# MIMXRT1015 register map
Vendor: nxp.com; File version: 1.0
CPU: CM7 r0p1, little endian, MPU, FPU, VTOR, 4 interrupt priority bits
Registers are 32-bit, read-write, reset 0x0 unless marked. A register's access mark holds for its fields unless they carry their own. Offsets are from the block's base; [hi:lo] are bit positions; {n}, {i} and the like mark numbered series; 'fields as' and 'values as' point back to an identical list.

## IOMUXC (part 2 of 2)
Base 0x401F8000; register names take the prefix IOMUXC_
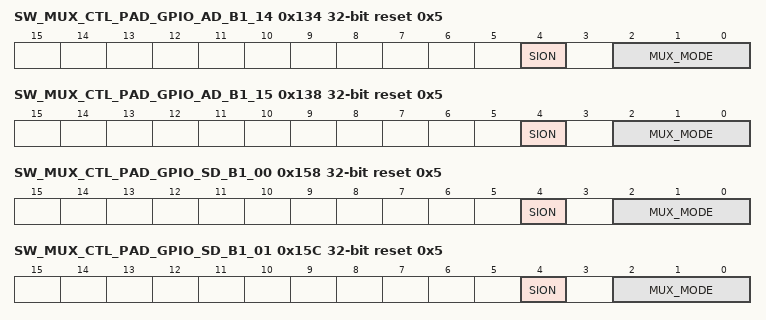
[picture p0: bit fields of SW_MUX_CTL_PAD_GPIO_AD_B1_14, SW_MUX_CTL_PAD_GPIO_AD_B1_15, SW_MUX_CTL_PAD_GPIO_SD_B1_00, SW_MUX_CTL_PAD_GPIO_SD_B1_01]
0x134 SW_MUX_CTL_PAD_GPIO_AD_B1_14 reset 0x5 — SW_MUX_CTL_PAD_GPIO_AD_B1_14 SW MUX Control Register
  [4] SION — Software Input On Field.
    0=DISABLED (Input Path is determined by functionality); 1=ENABLED (Force input path of pad GPIO_AD_B1_14)
  [2:0] MUX_MODE — MUX Mode Select Field.
    0=ALT0 (Select mux mode: ALT0 mux port: LPI2C1_SCL of instance: lpi2c1); 1=ALT1 (Select mux mode: ALT1 mux port: ACMP_OUT02 of instance: acmp); 4=ALT4 (Select mux mode: ALT4 mux port: FLEXIO1_FLEXIO01 of instance: flexio1); 5=ALT5 (Select mux mode: ALT5 mux port: GPIO1_IO30 of instance: gpio1)
0x138 SW_MUX_CTL_PAD_GPIO_AD_B1_15 reset 0x5 — SW_MUX_CTL_PAD_GPIO_AD_B1_15 SW MUX Control Register
  [4] SION — Software Input On Field.
    0=DISABLED (Input Path is determined by functionality); 1=ENABLED (Force input path of pad GPIO_AD_B1_15)
  [2:0] MUX_MODE — MUX Mode Select Field.
    0=ALT0 (Select mux mode: ALT0 mux port: LPI2C1_SDA of instance: lpi2c1); 1=ALT1 (Select mux mode: ALT1 mux port: ACMP_OUT03 of instance: acmp); 4=ALT4 (Select mux mode: ALT4 mux port: FLEXIO1_FLEXIO00 of instance: flexio1); 5=ALT5 (Select mux mode: ALT5 mux port: GPIO1_IO31 of instance: gpio1); 6=ALT6 (Select mux mode: ALT6 mux port: CCM_DI0_EXT_CLK of instance: ccm)
0x158 SW_MUX_CTL_PAD_GPIO_SD_B1_00 reset 0x5 — SW_MUX_CTL_PAD_GPIO_SD_B1_00 SW MUX Control Register
  [4] SION — Software Input On Field.
    0=DISABLED (Input Path is determined by functionality); 1=ENABLED (Force input path of pad GPIO_SD_B1_00)
  [2:0] MUX_MODE — MUX Mode Select Field.
    1=ALT1 (Select mux mode: ALT1 mux port: FLEXSPI_B_DATA03 of instance: flexspi); 3=ALT3 (Select mux mode: ALT3 mux port: XBAR1_XBAR_INOUT10 of instance: xbar1); 5=ALT5 (Select mux mode: ALT5 mux port: GPIO3_IO20 of instance: gpio3)
0x15C SW_MUX_CTL_PAD_GPIO_SD_B1_01 reset 0x5 — SW_MUX_CTL_PAD_GPIO_SD_B1_01 SW MUX Control Register
  [4] SION — Software Input On Field.
    0=DISABLED (Input Path is determined by functionality); 1=ENABLED (Force input path of pad GPIO_SD_B1_01)
  [2:0] MUX_MODE — MUX Mode Select Field.
    1=ALT1 (Select mux mode: ALT1 mux port: FLEXSPI_B_SCLK of instance: flexspi); 3=ALT3 (Select mux mode: ALT3 mux port: FLEXSPI_A_SS1_B of instance: flexspi); 5=ALT5 (Select mux mode: ALT5 mux port: GPIO3_IO21 of instance: gpio3)
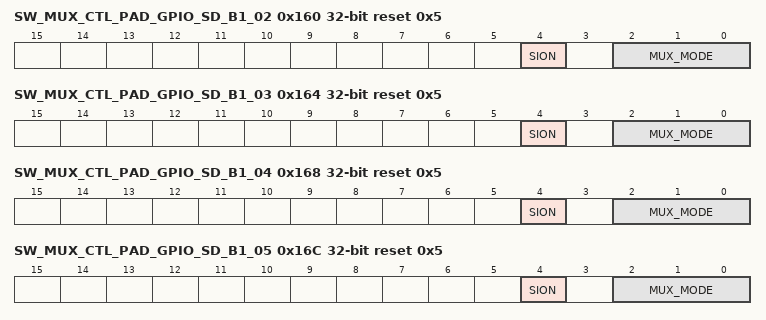
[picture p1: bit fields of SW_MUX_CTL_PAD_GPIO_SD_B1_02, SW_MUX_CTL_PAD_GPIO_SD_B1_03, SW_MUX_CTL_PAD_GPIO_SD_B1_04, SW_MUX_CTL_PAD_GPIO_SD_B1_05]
0x160 SW_MUX_CTL_PAD_GPIO_SD_B1_02 reset 0x5 — SW_MUX_CTL_PAD_GPIO_SD_B1_02 SW MUX Control Register
  [4] SION — Software Input On Field.
    0=DISABLED (Input Path is determined by functionality); 1=ENABLED (Force input path of pad GPIO_SD_B1_02)
  [2:0] MUX_MODE — MUX Mode Select Field.
    1=ALT1 (Select mux mode: ALT1 mux port: FLEXSPI_B_DATA00 of instance: flexspi); 5=ALT5 (Select mux mode: ALT5 mux port: GPIO3_IO22 of instance: gpio3); 6=ALT6 (Select mux mode: ALT6 mux port: CCM_CLKO1 of instance: ccm)
0x164 SW_MUX_CTL_PAD_GPIO_SD_B1_03 reset 0x5 — SW_MUX_CTL_PAD_GPIO_SD_B1_03 SW MUX Control Register
  [4] SION — Software Input On Field.
    0=DISABLED (Input Path is determined by functionality); 1=ENABLED (Force input path of pad GPIO_SD_B1_03)
  [2:0] MUX_MODE — MUX Mode Select Field.
    1=ALT1 (Select mux mode: ALT1 mux port: FLEXSPI_B_DATA02 of instance: flexspi); 5=ALT5 (Select mux mode: ALT5 mux port: GPIO3_IO23 of instance: gpio3); 6=ALT6 (Select mux mode: ALT6 mux port: CCM_CLKO2 of instance: ccm)
0x168 SW_MUX_CTL_PAD_GPIO_SD_B1_04 reset 0x5 — SW_MUX_CTL_PAD_GPIO_SD_B1_04 SW MUX Control Register
  [4] SION — Software Input On Field.
    0=DISABLED (Input Path is determined by functionality); 1=ENABLED (Force input path of pad GPIO_SD_B1_04)
  [2:0] MUX_MODE — MUX Mode Select Field.
    1=ALT1 (Select mux mode: ALT1 mux port: FLEXSPI_B_DATA01 of instance: flexspi); 4=ALT4 (Select mux mode: ALT4 mux port: EWM_EWM_OUT_B of instance: ewm); 5=ALT5 (Select mux mode: ALT5 mux port: GPIO3_IO24 of instance: gpio3); 6=ALT6 (Select mux mode: ALT6 mux port: CCM_WAIT of instance: ccm)
0x16C SW_MUX_CTL_PAD_GPIO_SD_B1_05 reset 0x5 — SW_MUX_CTL_PAD_GPIO_SD_B1_05 SW MUX Control Register
  [4] SION — Software Input On Field.
    0=DISABLED (Input Path is determined by functionality); 1=ENABLED (Force input path of pad GPIO_SD_B1_05)
  [2:0] MUX_MODE — MUX Mode Select Field.
    1=ALT1 (Select mux mode: ALT1 mux port: FLEXSPI_A_DQS of instance: flexspi); 3=ALT3 (Select mux mode: ALT3 mux port: SAI3_MCLK of instance: sai3); 4=ALT4 (Select mux mode: ALT4 mux port: FLEXSPI_B_SS0_B of instance: flexspi); 5=ALT5 (Select mux mode: ALT5 mux port: GPIO3_IO25 of instance: gpio3); 6=ALT6 (Select mux mode: ALT6 mux port: CCM_PMIC_RDY of instance: ccm)
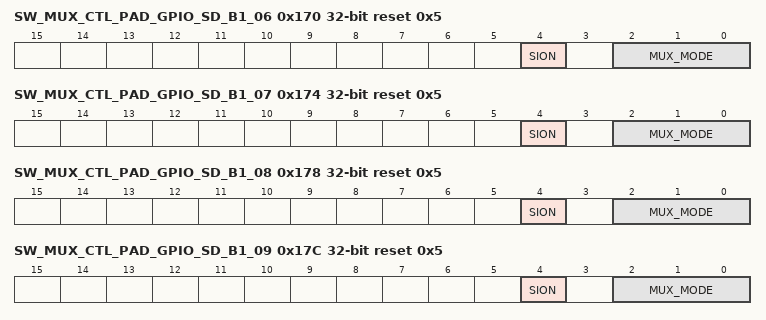
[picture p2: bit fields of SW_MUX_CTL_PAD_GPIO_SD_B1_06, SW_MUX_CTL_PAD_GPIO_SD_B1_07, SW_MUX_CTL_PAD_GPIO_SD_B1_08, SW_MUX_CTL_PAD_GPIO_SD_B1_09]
0x170 SW_MUX_CTL_PAD_GPIO_SD_B1_06 reset 0x5 — SW_MUX_CTL_PAD_GPIO_SD_B1_06 SW MUX Control Register
  [4] SION — Software Input On Field.
    0=DISABLED (Input Path is determined by functionality); 1=ENABLED (Force input path of pad GPIO_SD_B1_06)
  [2:0] MUX_MODE — MUX Mode Select Field.
    1=ALT1 (Select mux mode: ALT1 mux port: FLEXSPI_A_DATA03 of instance: flexspi); 3=ALT3 (Select mux mode: ALT3 mux port: SAI3_TX_BCLK of instance: sai3); 4=ALT4 (Select mux mode: ALT4 mux port: LPSPI2_PCS0 of instance: lpspi2); 5=ALT5 (Select mux mode: ALT5 mux port: GPIO3_IO26 of instance: gpio3); 6=ALT6 (Select mux mode: ALT6 mux port: CCM_STOP of instance: ccm)
0x174 SW_MUX_CTL_PAD_GPIO_SD_B1_07 reset 0x5 — SW_MUX_CTL_PAD_GPIO_SD_B1_07 SW MUX Control Register
  [4] SION — Software Input On Field.
    0=DISABLED (Input Path is determined by functionality); 1=ENABLED (Force input path of pad GPIO_SD_B1_07)
  [2:0] MUX_MODE — MUX Mode Select Field.
    1=ALT1 (Select mux mode: ALT1 mux port: FLEXSPI_A_SCLK of instance: flexspi); 3=ALT3 (Select mux mode: ALT3 mux port: SAI3_TX_SYNC of instance: sai3); 4=ALT4 (Select mux mode: ALT4 mux port: LPSPI2_SCK of instance: lpspi2); 5=ALT5 (Select mux mode: ALT5 mux port: GPIO3_IO27 of instance: gpio3)
0x178 SW_MUX_CTL_PAD_GPIO_SD_B1_08 reset 0x5 — SW_MUX_CTL_PAD_GPIO_SD_B1_08 SW MUX Control Register
  [4] SION — Software Input On Field.
    0=DISABLED (Input Path is determined by functionality); 1=ENABLED (Force input path of pad GPIO_SD_B1_08)
  [2:0] MUX_MODE — MUX Mode Select Field.
    1=ALT1 (Select mux mode: ALT1 mux port: FLEXSPI_A_DATA00 of instance: flexspi); 3=ALT3 (Select mux mode: ALT3 mux port: SAI3_TX_DATA of instance: sai3); 4=ALT4 (Select mux mode: ALT4 mux port: LPSPI2_SDO of instance: lpspi2); 5=ALT5 (Select mux mode: ALT5 mux port: GPIO3_IO28 of instance: gpio3)
0x17C SW_MUX_CTL_PAD_GPIO_SD_B1_09 reset 0x5 — SW_MUX_CTL_PAD_GPIO_SD_B1_09 SW MUX Control Register
  [4] SION — Software Input On Field.
    0=DISABLED (Input Path is determined by functionality); 1=ENABLED (Force input path of pad GPIO_SD_B1_09)
  [2:0] MUX_MODE — MUX Mode Select Field.
    1=ALT1 (Select mux mode: ALT1 mux port: FLEXSPI_A_DATA02 of instance: flexspi); 3=ALT3 (Select mux mode: ALT3 mux port: SAI3_RX_BCLK of instance: sai3); 4=ALT4 (Select mux mode: ALT4 mux port: LPSPI2_SDI of instance: lpspi2); 5=ALT5 (Select mux mode: ALT5 mux port: GPIO3_IO29 of instance: gpio3); 6=ALT6 (Select mux mode: ALT6 mux port: CCM_REF_EN_B of instance: ccm)
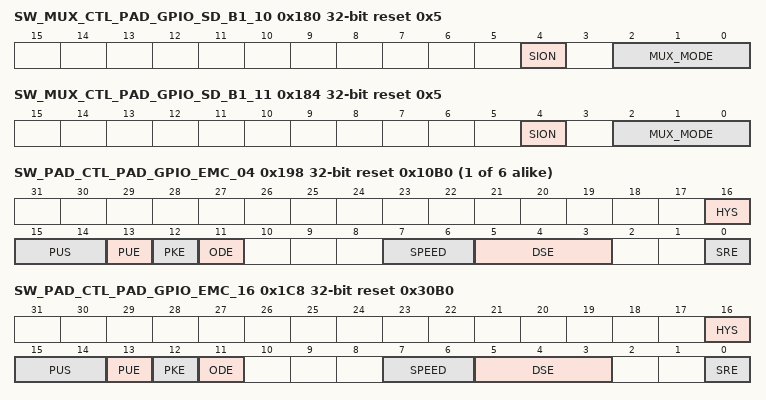
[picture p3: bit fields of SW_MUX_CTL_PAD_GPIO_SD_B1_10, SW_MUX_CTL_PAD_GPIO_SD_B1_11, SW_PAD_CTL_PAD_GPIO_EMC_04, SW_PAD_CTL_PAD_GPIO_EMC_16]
0x180 SW_MUX_CTL_PAD_GPIO_SD_B1_10 reset 0x5 — SW_MUX_CTL_PAD_GPIO_SD_B1_10 SW MUX Control Register
  [4] SION — Software Input On Field.
    0=DISABLED (Input Path is determined by functionality); 1=ENABLED (Force input path of pad GPIO_SD_B1_10)
  [2:0] MUX_MODE — MUX Mode Select Field.
    1=ALT1 (Select mux mode: ALT1 mux port: FLEXSPI_A_DATA01 of instance: flexspi); 3=ALT3 (Select mux mode: ALT3 mux port: SAI3_RX_SYNC of instance: sai3); 4=ALT4 (Select mux mode: ALT4 mux port: LPSPI2_PCS2 of instance: lpspi2); 5=ALT5 (Select mux mode: ALT5 mux port: GPIO3_IO30 of instance: gpio3)
0x184 SW_MUX_CTL_PAD_GPIO_SD_B1_11 reset 0x5 — SW_MUX_CTL_PAD_GPIO_SD_B1_11 SW MUX Control Register
  [4] SION — Software Input On Field.
    0=DISABLED (Input Path is determined by functionality); 1=ENABLED (Force input path of pad GPIO_SD_B1_11)
  [2:0] MUX_MODE — MUX Mode Select Field.
    1=ALT1 (Select mux mode: ALT1 mux port: FLEXSPI_A_SS0_B of instance: flexspi); 3=ALT3 (Select mux mode: ALT3 mux port: SAI3_RX_DATA of instance: sai3); 4=ALT4 (Select mux mode: ALT4 mux port: LPSPI2_PCS3 of instance: lpspi2); 5=ALT5 (Select mux mode: ALT5 mux port: GPIO3_IO31 of instance: gpio3)
{0x188+4i} SW_PAD_CTL_PAD_GPIO_EMC_{i:02} reset 0x10B0 (i=4..9) — SW_PAD_CTL_PAD_GPIO_EMC_{i:02} SW PAD Control Register
  [16] HYS — Hyst. Enable Field
    0=HYS_0_Hysteresis_Disabled (Hysteresis Disabled); 1=HYS_1_Hysteresis_Enabled (Hysteresis Enabled)
  [15:14] PUS — Pull Up / Down Config. Field
    0=PUS_0_100K_Ohm_Pull_Down (100K Ohm Pull Down); 1=PUS_1_47K_Ohm_Pull_Up (47K Ohm Pull Up); 2=PUS_2_100K_Ohm_Pull_Up (100K Ohm Pull Up); 3=PUS_3_22K_Ohm_Pull_Up (22K Ohm Pull Up)
  [13] PUE — Pull / Keep Select Field
    0=PUE_0_Keeper (Keeper); 1=PUE_1_Pull (Pull)
  [12] PKE — Pull / Keep Enable Field
    0=PKE_0_Pull_Keeper_Disabled (Pull/Keeper Disabled); 1=PKE_1_Pull_Keeper_Enabled (Pull/Keeper Enabled)
  [11] ODE — Open Drain Enable Field
    0=ODE_0_Open_Drain_Disabled (Open Drain Disabled); 1=ODE_1_Open_Drain_Enabled (Open Drain Enabled)
  [7:6] SPEED
    0=SPEED_0_low_50MHz_ (low(50MHz)); 1=SPEED_1_medium_100MHz_ (medium(100MHz)); 2=SPEED_2_medium_100MHz_ (medium(100MHz)); 3=SPEED_3_max_200MHz_ (max(200MHz))
  [5:3] DSE — Drive Strength Field
    0=DSE_0_output_driver_disabled_ (output driver disabled;); 1=DSE_1_R0_150_Ohm___3_3V__260_Ohm_1_8V (R0(150 Ohm @ 3.3V, 260 Ohm@1.8V)); {v}=DSE_{v}_R0_{v} (R0/{v}) (v=2..7)
  [0] SRE — Slew Rate Field
    0=SRE_0_Slow_Slew_Rate (Slow Slew Rate); 1=SRE_1_Fast_Slew_Rate (Fast Slew Rate)
0x1C8 SW_PAD_CTL_PAD_GPIO_EMC_16 reset 0x30B0 — SW_PAD_CTL_PAD_GPIO_EMC_16 SW PAD Control Register
  fields as SW_PAD_CTL_PAD_GPIO_EMC_04
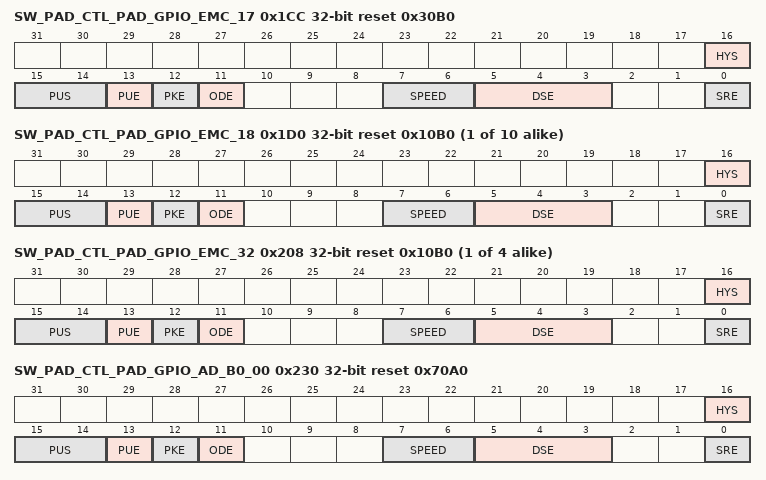
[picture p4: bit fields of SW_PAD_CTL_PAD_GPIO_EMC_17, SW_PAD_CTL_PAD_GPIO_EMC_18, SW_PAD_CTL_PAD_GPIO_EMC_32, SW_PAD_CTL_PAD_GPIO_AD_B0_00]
0x1CC SW_PAD_CTL_PAD_GPIO_EMC_17 reset 0x30B0 — SW_PAD_CTL_PAD_GPIO_EMC_17 SW PAD Control Register
  fields as SW_PAD_CTL_PAD_GPIO_EMC_04
{0x188+4i} SW_PAD_CTL_PAD_GPIO_EMC_{i} reset 0x10B0 (i=18..27) — SW_PAD_CTL_PAD_GPIO_EMC_{i} SW PAD Control Register
  fields as SW_PAD_CTL_PAD_GPIO_EMC_04
{0x188+4i} SW_PAD_CTL_PAD_GPIO_EMC_{i} reset 0x10B0 (i=32..35) — SW_PAD_CTL_PAD_GPIO_EMC_{i} SW PAD Control Register
  fields as SW_PAD_CTL_PAD_GPIO_EMC_04
0x230 SW_PAD_CTL_PAD_GPIO_AD_B0_00 reset 0x70A0 — SW_PAD_CTL_PAD_GPIO_AD_B0_00 SW PAD Control Register
  fields as SW_PAD_CTL_PAD_GPIO_EMC_04
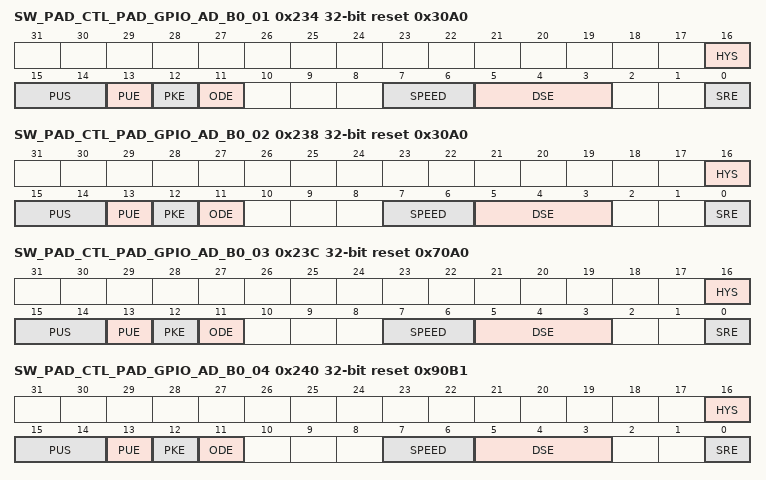
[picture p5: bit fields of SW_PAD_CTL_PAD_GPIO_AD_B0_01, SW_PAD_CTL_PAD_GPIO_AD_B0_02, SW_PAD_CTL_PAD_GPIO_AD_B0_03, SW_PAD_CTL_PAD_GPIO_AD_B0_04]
0x234 SW_PAD_CTL_PAD_GPIO_AD_B0_01 reset 0x30A0 — SW_PAD_CTL_PAD_GPIO_AD_B0_01 SW PAD Control Register
  fields as SW_PAD_CTL_PAD_GPIO_EMC_04
0x238 SW_PAD_CTL_PAD_GPIO_AD_B0_02 reset 0x30A0 — SW_PAD_CTL_PAD_GPIO_AD_B0_02 SW PAD Control Register
  fields as SW_PAD_CTL_PAD_GPIO_EMC_04
0x23C SW_PAD_CTL_PAD_GPIO_AD_B0_03 reset 0x70A0 — SW_PAD_CTL_PAD_GPIO_AD_B0_03 SW PAD Control Register
  fields as SW_PAD_CTL_PAD_GPIO_EMC_04
0x240 SW_PAD_CTL_PAD_GPIO_AD_B0_04 reset 0x90B1 — SW_PAD_CTL_PAD_GPIO_AD_B0_04 SW PAD Control Register
  fields as SW_PAD_CTL_PAD_GPIO_EMC_04
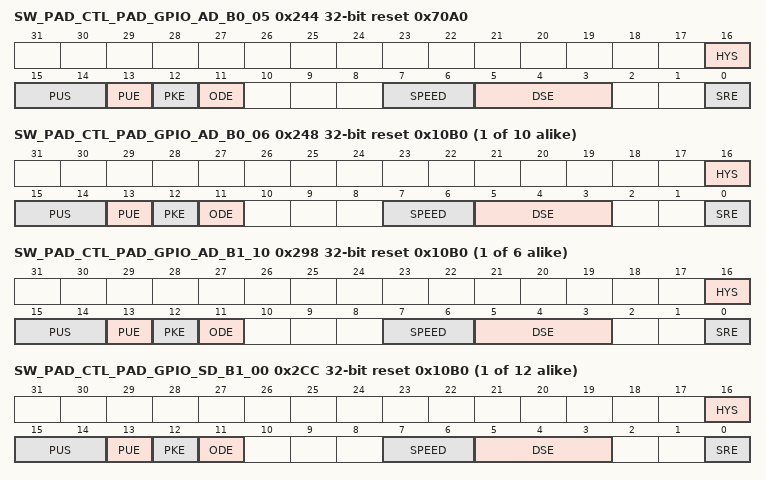
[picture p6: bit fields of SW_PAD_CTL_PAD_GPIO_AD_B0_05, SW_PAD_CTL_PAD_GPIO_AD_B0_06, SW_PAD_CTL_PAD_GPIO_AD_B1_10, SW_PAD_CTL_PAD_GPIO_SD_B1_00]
0x244 SW_PAD_CTL_PAD_GPIO_AD_B0_05 reset 0x70A0 — SW_PAD_CTL_PAD_GPIO_AD_B0_05 SW PAD Control Register
  fields as SW_PAD_CTL_PAD_GPIO_EMC_04
{0x230+4i} SW_PAD_CTL_PAD_GPIO_AD_B0_{i:02} reset 0x10B0 (i=6..15) — SW_PAD_CTL_PAD_GPIO_AD_B0_{i:02} SW PAD Control Register
  fields as SW_PAD_CTL_PAD_GPIO_EMC_04
{0x270+4i} SW_PAD_CTL_PAD_GPIO_AD_B1_{i} reset 0x10B0 (i=10..15) — SW_PAD_CTL_PAD_GPIO_AD_B1_{i} SW PAD Control Register
  fields as SW_PAD_CTL_PAD_GPIO_EMC_04
{0x2CC+4i} SW_PAD_CTL_PAD_GPIO_SD_B1_{i:02} reset 0x10B0 (i=0..11) — SW_PAD_CTL_PAD_GPIO_SD_B1_{i:02} SW PAD Control Register
  fields as SW_PAD_CTL_PAD_GPIO_EMC_04
0x2FC ANATOP_USB_OTG_ID_SELECT_INPUT — ANATOP_USB_OTG_ID_SELECT_INPUT DAISY Register
  [1:0] DAISY — Selecting Pads Involved in Daisy Chain.
    0=GPIO_AD_B0_05_ALT6 (Selecting Pad: GPIO_AD_B0_05 for Mode: ALT6); 1=GPIO_AD_B1_11_ALT0 (Selecting Pad: GPIO_AD_B1_11 for Mode: ALT0)
0x300 CCM_PMIC_VFUNCIONAL_READY_SELECT_INPUT — CCM_PMIC_VFUNCIONAL_READY_SELECT_INPUT DAISY Register
  [1:0] DAISY — Selecting Pads Involved in Daisy Chain.
    1=GPIO_SD_B1_05_ALT6 (Selecting Pad: GPIO_SD_B1_05 for Mode: ALT6); 2=GPIO_AD_B0_03_ALT7 (Selecting Pad: GPIO_AD_B0_03 for Mode: ALT7)
0x328 FLEXPWM1_IPP_IND_PWMA_SELECT_INPUT_0 — FLEXPWM1_IPP_IND_PWMA_SELECT_INPUT_0 DAISY Register
  [0] DAISY — Selecting Pads Involved in Daisy Chain.
    1=GPIO_EMC_26_ALT1 (Selecting Pad: GPIO_EMC_26 for Mode: ALT1)
0x32C FLEXPWM1_IPP_IND_PWMA_SELECT_INPUT_1 — FLEXPWM1_IPP_IND_PWMA_SELECT_INPUT_1 DAISY Register
  [0] DAISY — Selecting Pads Involved in Daisy Chain.
    1=GPIO_EMC_24_ALT1 (Selecting Pad: GPIO_EMC_24 for Mode: ALT1)
0x330 FLEXPWM1_IPP_IND_PWMA_SELECT_INPUT_2 — FLEXPWM1_IPP_IND_PWMA_SELECT_INPUT_2 DAISY Register
  [0] DAISY — Selecting Pads Involved in Daisy Chain.
    0=GPIO_AD_B1_10_ALT1 (Selecting Pad: GPIO_AD_B1_10 for Mode: ALT1); 1=GPIO_EMC_22_ALT1 (Selecting Pad: GPIO_EMC_22 for Mode: ALT1)
0x334 FLEXPWM1_IPP_IND_PWMA_SELECT_INPUT_3 — FLEXPWM1_IPP_IND_PWMA_SELECT_INPUT_3 DAISY Register
  [0] DAISY — Selecting Pads Involved in Daisy Chain.
    0=GPIO_AD_B1_12_ALT6 (Selecting Pad: GPIO_AD_B1_12 for Mode: ALT6); 1=GPIO_EMC_20_ALT1 (Selecting Pad: GPIO_EMC_20 for Mode: ALT1)
0x338 FLEXPWM1_IPP_IND_PWMB_SELECT_INPUT_0 — FLEXPWM1_IPP_IND_PWMB_SELECT_INPUT_0 DAISY Register
  [0] DAISY — Selecting Pads Involved in Daisy Chain.
    1=GPIO_EMC_27_ALT1 (Selecting Pad: GPIO_EMC_27 for Mode: ALT1)
0x33C FLEXPWM1_IPP_IND_PWMB_SELECT_INPUT_1 — FLEXPWM1_IPP_IND_PWMB_SELECT_INPUT_1 DAISY Register
  [0] DAISY — Selecting Pads Involved in Daisy Chain.
    1=GPIO_EMC_25_ALT1 (Selecting Pad: GPIO_EMC_25 for Mode: ALT1)
0x340 FLEXPWM1_IPP_IND_PWMB_SELECT_INPUT_2 — FLEXPWM1_IPP_IND_PWMB_SELECT_INPUT_2 DAISY Register
  [0] DAISY — Selecting Pads Involved in Daisy Chain.
    0=GPIO_AD_B1_11_ALT1 (Selecting Pad: GPIO_AD_B1_11 for Mode: ALT1); 1=GPIO_EMC_23_ALT1 (Selecting Pad: GPIO_EMC_23 for Mode: ALT1)
0x344 FLEXPWM1_IPP_IND_PWMB_SELECT_INPUT_3 — FLEXPWM1_IPP_IND_PWMB_SELECT_INPUT_3 DAISY Register
  [0] DAISY — Selecting Pads Involved in Daisy Chain.
    0=GPIO_AD_B1_13_ALT6 (Selecting Pad: GPIO_AD_B1_13 for Mode: ALT6); 1=GPIO_EMC_21_ALT1 (Selecting Pad: GPIO_EMC_21 for Mode: ALT1)
0x368 FLEXSPI_IPP_IND_IO_FA_BIT0_SELECT_INPUT — FLEXSPI_IPP_IND_IO_FA_BIT0_SELECT_INPUT DAISY Register
  [0] DAISY — Selecting Pads Involved in Daisy Chain.
    0=GPIO_SD_B1_08_ALT1 (Selecting Pad: GPIO_SD_B1_08 for Mode: ALT1)
0x36C FLEXSPI_IPP_IND_IO_FA_BIT1_SELECT_INPUT — FLEXSPI_IPP_IND_IO_FA_BIT1_SELECT_INPUT DAISY Register
  [0] DAISY — Selecting Pads Involved in Daisy Chain.
    0=GPIO_SD_B1_10_ALT1 (Selecting Pad: GPIO_SD_B1_10 for Mode: ALT1)
0x370 FLEXSPI_IPP_IND_IO_FA_BIT2_SELECT_INPUT — FLEXSPI_IPP_IND_IO_FA_BIT2_SELECT_INPUT DAISY Register
  [0] DAISY — Selecting Pads Involved in Daisy Chain.
    0=GPIO_SD_B1_09_ALT1 (Selecting Pad: GPIO_SD_B1_09 for Mode: ALT1)
0x374 FLEXSPI_IPP_IND_IO_FA_BIT3_SELECT_INPUT — FLEXSPI_IPP_IND_IO_FA_BIT3_SELECT_INPUT DAISY Register
  [0] DAISY — Selecting Pads Involved in Daisy Chain.
    0=GPIO_SD_B1_06_ALT1 (Selecting Pad: GPIO_SD_B1_06 for Mode: ALT1)
0x378 FLEXSPI_IPP_IND_SCK_FA_SELECT_INPUT — FLEXSPI_IPP_IND_SCK_FA_SELECT_INPUT DAISY Register
  [0] DAISY — Selecting Pads Involved in Daisy Chain.
    0=GPIO_SD_B1_07_ALT1 (Selecting Pad: GPIO_SD_B1_07 for Mode: ALT1)
0x37C LPI2C1_IPP_IND_LPI2C_SCL_SELECT_INPUT — LPI2C1_IPP_IND_LPI2C_SCL_SELECT_INPUT DAISY Register
  [0] DAISY — Selecting Pads Involved in Daisy Chain.
    1=GPIO_AD_B1_14_ALT0 (Selecting Pad: GPIO_AD_B1_14 for Mode: ALT0)
0x380 LPI2C1_IPP_IND_LPI2C_SDA_SELECT_INPUT — LPI2C1_IPP_IND_LPI2C_SDA_SELECT_INPUT DAISY Register
  [0] DAISY — Selecting Pads Involved in Daisy Chain.
    1=GPIO_AD_B1_15_ALT0 (Selecting Pad: GPIO_AD_B1_15 for Mode: ALT0)
0x384 LPI2C2_IPP_IND_LPI2C_SCL_SELECT_INPUT — LPI2C2_IPP_IND_LPI2C_SCL_SELECT_INPUT DAISY Register
  [0] DAISY — Selecting Pads Involved in Daisy Chain.
    1=GPIO_EMC_19_ALT2 (Selecting Pad: GPIO_EMC_19 for Mode: ALT2)
0x388 LPI2C2_IPP_IND_LPI2C_SDA_SELECT_INPUT — LPI2C2_IPP_IND_LPI2C_SDA_SELECT_INPUT DAISY Register
  [0] DAISY — Selecting Pads Involved in Daisy Chain.
    1=GPIO_EMC_18_ALT2 (Selecting Pad: GPIO_EMC_18 for Mode: ALT2)
0x39C LPSPI1_IPP_IND_LPSPI_PCS_SELECT_INPUT_0 — LPSPI1_IPP_IND_LPSPI_PCS_SELECT_INPUT_0 DAISY Register
  [0] DAISY — Selecting Pads Involved in Daisy Chain.
    1=GPIO_AD_B0_11_ALT1 (Selecting Pad: GPIO_AD_B0_11 for Mode: ALT1)
0x3A0 LPSPI1_IPP_IND_LPSPI_SCK_SELECT_INPUT — LPSPI1_IPP_IND_LPSPI_SCK_SELECT_INPUT DAISY Register
  [0] DAISY — Selecting Pads Involved in Daisy Chain.
    1=GPIO_AD_B0_10_ALT1 (Selecting Pad: GPIO_AD_B0_10 for Mode: ALT1)
0x3A4 LPSPI1_IPP_IND_LPSPI_SDI_SELECT_INPUT — LPSPI1_IPP_IND_LPSPI_SDI_SELECT_INPUT DAISY Register
  [0] DAISY — Selecting Pads Involved in Daisy Chain.
    1=GPIO_AD_B0_13_ALT1 (Selecting Pad: GPIO_AD_B0_13 for Mode: ALT1)
0x3A8 LPSPI1_IPP_IND_LPSPI_SDO_SELECT_INPUT — LPSPI1_IPP_IND_LPSPI_SDO_SELECT_INPUT DAISY Register
  [0] DAISY — Selecting Pads Involved in Daisy Chain.
    1=GPIO_AD_B0_12_ALT1 (Selecting Pad: GPIO_AD_B0_12 for Mode: ALT1)
0x3AC LPSPI2_IPP_IND_LPSPI_PCS_SELECT_INPUT_0 — LPSPI2_IPP_IND_LPSPI_PCS_SELECT_INPUT_0 DAISY Register
  [1:0] DAISY — Selecting Pads Involved in Daisy Chain.
    2=GPIO_SD_B1_06_ALT4 (Selecting Pad: GPIO_SD_B1_06 for Mode: ALT4)
0x3B0 LPSPI2_IPP_IND_LPSPI_SCK_SELECT_INPUT — LPSPI2_IPP_IND_LPSPI_SCK_SELECT_INPUT DAISY Register
  [1:0] DAISY — Selecting Pads Involved in Daisy Chain.
    2=GPIO_SD_B1_07_ALT4 (Selecting Pad: GPIO_SD_B1_07 for Mode: ALT4)
0x3B4 LPSPI2_IPP_IND_LPSPI_SDI_SELECT_INPUT — LPSPI2_IPP_IND_LPSPI_SDI_SELECT_INPUT DAISY Register
  [1:0] DAISY — Selecting Pads Involved in Daisy Chain.
    2=GPIO_SD_B1_09_ALT4 (Selecting Pad: GPIO_SD_B1_09 for Mode: ALT4)
0x3B8 LPSPI2_IPP_IND_LPSPI_SDO_SELECT_INPUT — LPSPI2_IPP_IND_LPSPI_SDO_SELECT_INPUT DAISY Register
  [1:0] DAISY — Selecting Pads Involved in Daisy Chain.
    2=GPIO_SD_B1_08_ALT4 (Selecting Pad: GPIO_SD_B1_08 for Mode: ALT4)
0x3CC LPUART2_IPP_IND_LPUART_CTS_B_SELECT_INPUT — LPUART2_IPP_IND_LPUART_CTS_B_SELECT_INPUT DAISY Register
  [0] DAISY — Selecting Pads Involved in Daisy Chain.
    1=GPIO_EMC_20_ALT2 (Selecting Pad: GPIO_EMC_20 for Mode: ALT2)
0x3D0 LPUART2_IPP_IND_LPUART_RXD_SELECT_INPUT — LPUART2_IPP_IND_LPUART_RXD_SELECT_INPUT DAISY Register
  [0] DAISY — Selecting Pads Involved in Daisy Chain.
    1=GPIO_EMC_23_ALT2 (Selecting Pad: GPIO_EMC_23 for Mode: ALT2)
0x3D4 LPUART2_IPP_IND_LPUART_TXD_SELECT_INPUT — LPUART2_IPP_IND_LPUART_TXD_SELECT_INPUT DAISY Register
  [0] DAISY — Selecting Pads Involved in Daisy Chain.
    1=GPIO_EMC_22_ALT2 (Selecting Pad: GPIO_EMC_22 for Mode: ALT2)
0x3D8 LPUART3_IPP_IND_LPUART_RXD_SELECT_INPUT — LPUART3_IPP_IND_LPUART_RXD_SELECT_INPUT DAISY Register
  [0] DAISY — Selecting Pads Involved in Daisy Chain.
    0=GPIO_EMC_07_ALT2 (Selecting Pad: GPIO_EMC_07 for Mode: ALT2); 1=GPIO_AD_B0_15_ALT2 (Selecting Pad: GPIO_AD_B0_15 for Mode: ALT2)
0x3DC LPUART3_IPP_IND_LPUART_TXD_SELECT_INPUT — LPUART3_IPP_IND_LPUART_TXD_SELECT_INPUT DAISY Register
  [0] DAISY — Selecting Pads Involved in Daisy Chain.
    0=GPIO_EMC_06_ALT2 (Selecting Pad: GPIO_EMC_06 for Mode: ALT2); 1=GPIO_AD_B0_14_ALT2 (Selecting Pad: GPIO_AD_B0_14 for Mode: ALT2)
0x3E0 LPUART4_IPP_IND_LPUART_CTS_B_SELECT_INPUT — LPUART4_IPP_IND_LPUART_CTS_B_SELECT_INPUT DAISY Register
  [0] DAISY — Selecting Pads Involved in Daisy Chain.
0x3E4 LPUART4_IPP_IND_LPUART_RXD_SELECT_INPUT — LPUART4_IPP_IND_LPUART_RXD_SELECT_INPUT DAISY Register
  [1:0] DAISY — Selecting Pads Involved in Daisy Chain.
    1=GPIO_AD_B1_11_ALT2 (Selecting Pad: GPIO_AD_B1_11 for Mode: ALT2); 2=GPIO_EMC_33_ALT2 (Selecting Pad: GPIO_EMC_33 for Mode: ALT2)
0x3E8 LPUART4_IPP_IND_LPUART_TXD_SELECT_INPUT — LPUART4_IPP_IND_LPUART_TXD_SELECT_INPUT DAISY Register
  [1:0] DAISY — Selecting Pads Involved in Daisy Chain.
    1=GPIO_AD_B1_10_ALT2 (Selecting Pad: GPIO_AD_B1_10 for Mode: ALT2); 2=GPIO_EMC_32_ALT2 (Selecting Pad: GPIO_EMC_32 for Mode: ALT2)
0x40C NMI_GLUE_IPP_IND_NMI_SELECT_INPUT — NMI_GLUE_IPP_IND_NMI_SELECT_INPUT DAISY Register
  [0] DAISY — Selecting Pads Involved in Daisy Chain.
    0=GPIO_AD_B0_05_ALT7 (Selecting Pad: GPIO_AD_B0_05 for Mode: ALT7); 1=WAKEUP_ALT7 (Selecting Pad: WAKEUP for Mode: ALT7)
{0x410+4i} QTIMER1_TMR{i}_INPUT_SELECT_INPUT (i=0..3) — QTIMER1_TMR{i}_INPUT_SELECT_INPUT DAISY Register
  [0] DAISY — Selecting Pads Involved in Daisy Chain.
    1=GPIO_EMC_{i+32}_ALT1 (Selecting Pad: GPIO_EMC_{i+32} for Mode: ALT1)
0x430 SAI1_IPG_CLK_SAI_MCLK_SELECT_INPUT_2 — SAI1_IPG_CLK_SAI_MCLK_SELECT_INPUT_2 DAISY Register
  [1:0] DAISY — Selecting Pads Involved in Daisy Chain.
    1=GPIO_AD_B0_03_ALT3 (Selecting Pad: GPIO_AD_B0_03 for Mode: ALT3); 3=GPIO_EMC_20_ALT3 (Selecting Pad: GPIO_EMC_20 for Mode: ALT3)
0x434 SAI1_IPP_IND_SAI_RXBCLK_SELECT_INPUT — SAI1_IPP_IND_SAI_RXBCLK_SELECT_INPUT DAISY Register
  [1:0] DAISY — Selecting Pads Involved in Daisy Chain.
    2=GPIO_EMC_19_ALT3 (Selecting Pad: GPIO_EMC_19 for Mode: ALT3)
0x438 SAI1_IPP_IND_SAI_RXDATA_SELECT_INPUT_0 — SAI1_IPP_IND_SAI_RXDATA_SELECT_INPUT_0 DAISY Register
  [1:0] DAISY — Selecting Pads Involved in Daisy Chain.
    2=GPIO_EMC_21_ALT3 (Selecting Pad: GPIO_EMC_21 for Mode: ALT3)
{0x438+4i} SAI1_IPP_IND_SAI_RXDATA_SELECT_INPUT_{i} (i=1..3) — SAI1_IPP_IND_SAI_RXDATA_SELECT_INPUT_{i} DAISY Register
  [0] DAISY — Selecting Pads Involved in Daisy Chain.
    1=GPIO_EMC_{i+21}_ALT3 (Selecting Pad: GPIO_EMC_{i+21} for Mode: ALT3)
0x448 SAI1_IPP_IND_SAI_RXSYNC_SELECT_INPUT — SAI1_IPP_IND_SAI_RXSYNC_SELECT_INPUT DAISY Register
  [1:0] DAISY — Selecting Pads Involved in Daisy Chain.
    2=GPIO_EMC_18_ALT3 (Selecting Pad: GPIO_EMC_18 for Mode: ALT3)
0x44C SAI1_IPP_IND_SAI_TXBCLK_SELECT_INPUT — SAI1_IPP_IND_SAI_TXBCLK_SELECT_INPUT DAISY Register
  [1:0] DAISY — Selecting Pads Involved in Daisy Chain.
    2=GPIO_EMC_26_ALT3 (Selecting Pad: GPIO_EMC_26 for Mode: ALT3)
0x450 SAI1_IPP_IND_SAI_TXSYNC_SELECT_INPUT — SAI1_IPP_IND_SAI_TXSYNC_SELECT_INPUT DAISY Register
  [1:0] DAISY — Selecting Pads Involved in Daisy Chain.
    2=GPIO_EMC_27_ALT3 (Selecting Pad: GPIO_EMC_27 for Mode: ALT3)
0x454 SAI2_IPG_CLK_SAI_MCLK_SELECT_INPUT_2 — SAI2_IPG_CLK_SAI_MCLK_SELECT_INPUT_2 DAISY Register
  [0] DAISY — Selecting Pads Involved in Daisy Chain.
    1=GPIO_EMC_16_ALT3 (Selecting Pad: GPIO_EMC_16 for Mode: ALT3)
0x458 SAI2_IPP_IND_SAI_RXBCLK_SELECT_INPUT — SAI2_IPP_IND_SAI_RXBCLK_SELECT_INPUT DAISY Register
  [0] DAISY — Selecting Pads Involved in Daisy Chain.
    1=GPIO_EMC_09_ALT3 (Selecting Pad: GPIO_EMC_09 for Mode: ALT3)
0x45C SAI2_IPP_IND_SAI_RXDATA_SELECT_INPUT_0 — SAI2_IPP_IND_SAI_RXDATA_SELECT_INPUT_0 DAISY Register
  [0] DAISY — Selecting Pads Involved in Daisy Chain.
    1=GPIO_EMC_08_ALT3 (Selecting Pad: GPIO_EMC_08 for Mode: ALT3)
0x460 SAI2_IPP_IND_SAI_RXSYNC_SELECT_INPUT — SAI2_IPP_IND_SAI_RXSYNC_SELECT_INPUT DAISY Register
  [0] DAISY — Selecting Pads Involved in Daisy Chain.
    1=GPIO_EMC_07_ALT3 (Selecting Pad: GPIO_EMC_07 for Mode: ALT3)
0x464 SAI2_IPP_IND_SAI_TXBCLK_SELECT_INPUT — SAI2_IPP_IND_SAI_TXBCLK_SELECT_INPUT DAISY Register
  [0] DAISY — Selecting Pads Involved in Daisy Chain.
    1=GPIO_EMC_04_ALT3 (Selecting Pad: GPIO_EMC_04 for Mode: ALT3)
0x468 SAI2_IPP_IND_SAI_TXSYNC_SELECT_INPUT — SAI2_IPP_IND_SAI_TXSYNC_SELECT_INPUT DAISY Register
  [0] DAISY — Selecting Pads Involved in Daisy Chain.
    1=GPIO_EMC_05_ALT3 (Selecting Pad: GPIO_EMC_05 for Mode: ALT3)
0x46C SAI3_IPG_CLK_SAI_MCLK_SELECT_INPUT_2 — SAI3_IPG_CLK_SAI_MCLK_SELECT_INPUT_2 DAISY Register
  [1:0] DAISY — Selecting Pads Involved in Daisy Chain.
    0=GPIO_SD_B1_05_ALT3 (Selecting Pad: GPIO_SD_B1_05 for Mode: ALT3); 1=GPIO_EMC_17_ALT3 (Selecting Pad: GPIO_EMC_17 for Mode: ALT3)
0x470 SAI3_IPP_IND_SAI_RXBCLK_SELECT_INPUT — SAI3_IPP_IND_SAI_RXBCLK_SELECT_INPUT DAISY Register
  [0] DAISY — Selecting Pads Involved in Daisy Chain.
    0=GPIO_SD_B1_09_ALT3 (Selecting Pad: GPIO_SD_B1_09 for Mode: ALT3)
0x474 SAI3_IPP_IND_SAI_RXDATA_SELECT_INPUT_0 — SAI3_IPP_IND_SAI_RXDATA_SELECT_INPUT_0 DAISY Register
  [0] DAISY — Selecting Pads Involved in Daisy Chain.
    0=GPIO_SD_B1_11_ALT3 (Selecting Pad: GPIO_SD_B1_11 for Mode: ALT3)
0x478 SAI3_IPP_IND_SAI_RXSYNC_SELECT_INPUT — SAI3_IPP_IND_SAI_RXSYNC_SELECT_INPUT DAISY Register
  [0] DAISY — Selecting Pads Involved in Daisy Chain.
    0=GPIO_SD_B1_10_ALT3 (Selecting Pad: GPIO_SD_B1_10 for Mode: ALT3)
0x47C SAI3_IPP_IND_SAI_TXBCLK_SELECT_INPUT — SAI3_IPP_IND_SAI_TXBCLK_SELECT_INPUT DAISY Register
  [0] DAISY — Selecting Pads Involved in Daisy Chain.
    0=GPIO_SD_B1_06_ALT3 (Selecting Pad: GPIO_SD_B1_06 for Mode: ALT3); 1=GPIO_EMC_33_ALT3 (Selecting Pad: GPIO_EMC_33 for Mode: ALT3)
0x480 SAI3_IPP_IND_SAI_TXSYNC_SELECT_INPUT — SAI3_IPP_IND_SAI_TXSYNC_SELECT_INPUT DAISY Register
  [0] DAISY — Selecting Pads Involved in Daisy Chain.
    0=GPIO_SD_B1_07_ALT3 (Selecting Pad: GPIO_SD_B1_07 for Mode: ALT3); 1=GPIO_EMC_34_ALT3 (Selecting Pad: GPIO_EMC_34 for Mode: ALT3)
0x488 SPDIF_SPDIF_IN1_SELECT_INPUT — SPDIF_SPDIF_IN1_SELECT_INPUT DAISY Register
  [0] DAISY — Selecting Pads Involved in Daisy Chain.
    0=GPIO_EMC_05_ALT2 (Selecting Pad: GPIO_EMC_05 for Mode: ALT2)
0x48C USB_IPP_IND_OTG_OC_SELECT_INPUT — USB_IPP_IND_OTG_OC_SELECT_INPUT DAISY Register
  [1:0] DAISY — Selecting Pads Involved in Daisy Chain.
    0=GPIO_AD_B0_03_ALT6 (Selecting Pad: GPIO_AD_B0_03 for Mode: ALT6); 1=GPIO_AD_B1_12_ALT0 (Selecting Pad: GPIO_AD_B1_12 for Mode: ALT0)
0x4A0 XBAR1_XBAR_IN_SELECT_INPUT_14 — XBAR1_XBAR_IN_SELECT_INPUT_14 DAISY Register
  [0] DAISY — Selecting Pads Involved in Daisy Chain.
0x4A4 XBAR1_XBAR_IN_SELECT_INPUT_15 — XBAR1_XBAR_IN_SELECT_INPUT_15 DAISY Register
  [0] DAISY — Selecting Pads Involved in Daisy Chain.
0x4A8 XBAR1_XBAR_IN_SELECT_INPUT_16 — XBAR1_XBAR_IN_SELECT_INPUT_16 DAISY Register
  [0] DAISY — Selecting Pads Involved in Daisy Chain.
    1=GPIO_EMC_18_ALT1 (Selecting Pad: GPIO_EMC_18 for Mode: ALT1)
0x4AC XBAR1_XBAR_IN_SELECT_INPUT_17 — XBAR1_XBAR_IN_SELECT_INPUT_17 DAISY Register
  [0] DAISY — Selecting Pads Involved in Daisy Chain.
    1=GPIO_EMC_19_ALT1 (Selecting Pad: GPIO_EMC_19 for Mode: ALT1)
0x4B0 XBAR1_XBAR_IN_SELECT_INPUT_10 — XBAR1_XBAR_IN_SELECT_INPUT_10 DAISY Register
  [0] DAISY — Selecting Pads Involved in Daisy Chain.
    1=GPIO_SD_B1_00_ALT3 (Selecting Pad: GPIO_SD_B1_00 for Mode: ALT3)
0x4B4 XBAR1_XBAR_IN_SELECT_INPUT_12 — XBAR1_XBAR_IN_SELECT_INPUT_12 DAISY Register
  [0] DAISY — Selecting Pads Involved in Daisy Chain.
0x4B8 XBAR1_XBAR_IN_SELECT_INPUT_13 — XBAR1_XBAR_IN_SELECT_INPUT_13 DAISY Register
  [0] DAISY — Selecting Pads Involved in Daisy Chain.
0x4BC XBAR1_XBAR_IN_SELECT_INPUT_18 — XBAR1_XBAR_IN_SELECT_INPUT_18 DAISY Register
  [0] DAISY — Selecting Pads Involved in Daisy Chain.
0x4C0 XBAR1_XBAR_IN_SELECT_INPUT_19 — XBAR1_XBAR_IN_SELECT_INPUT_19 DAISY Register
  [0] DAISY — Selecting Pads Involved in Daisy Chain.
